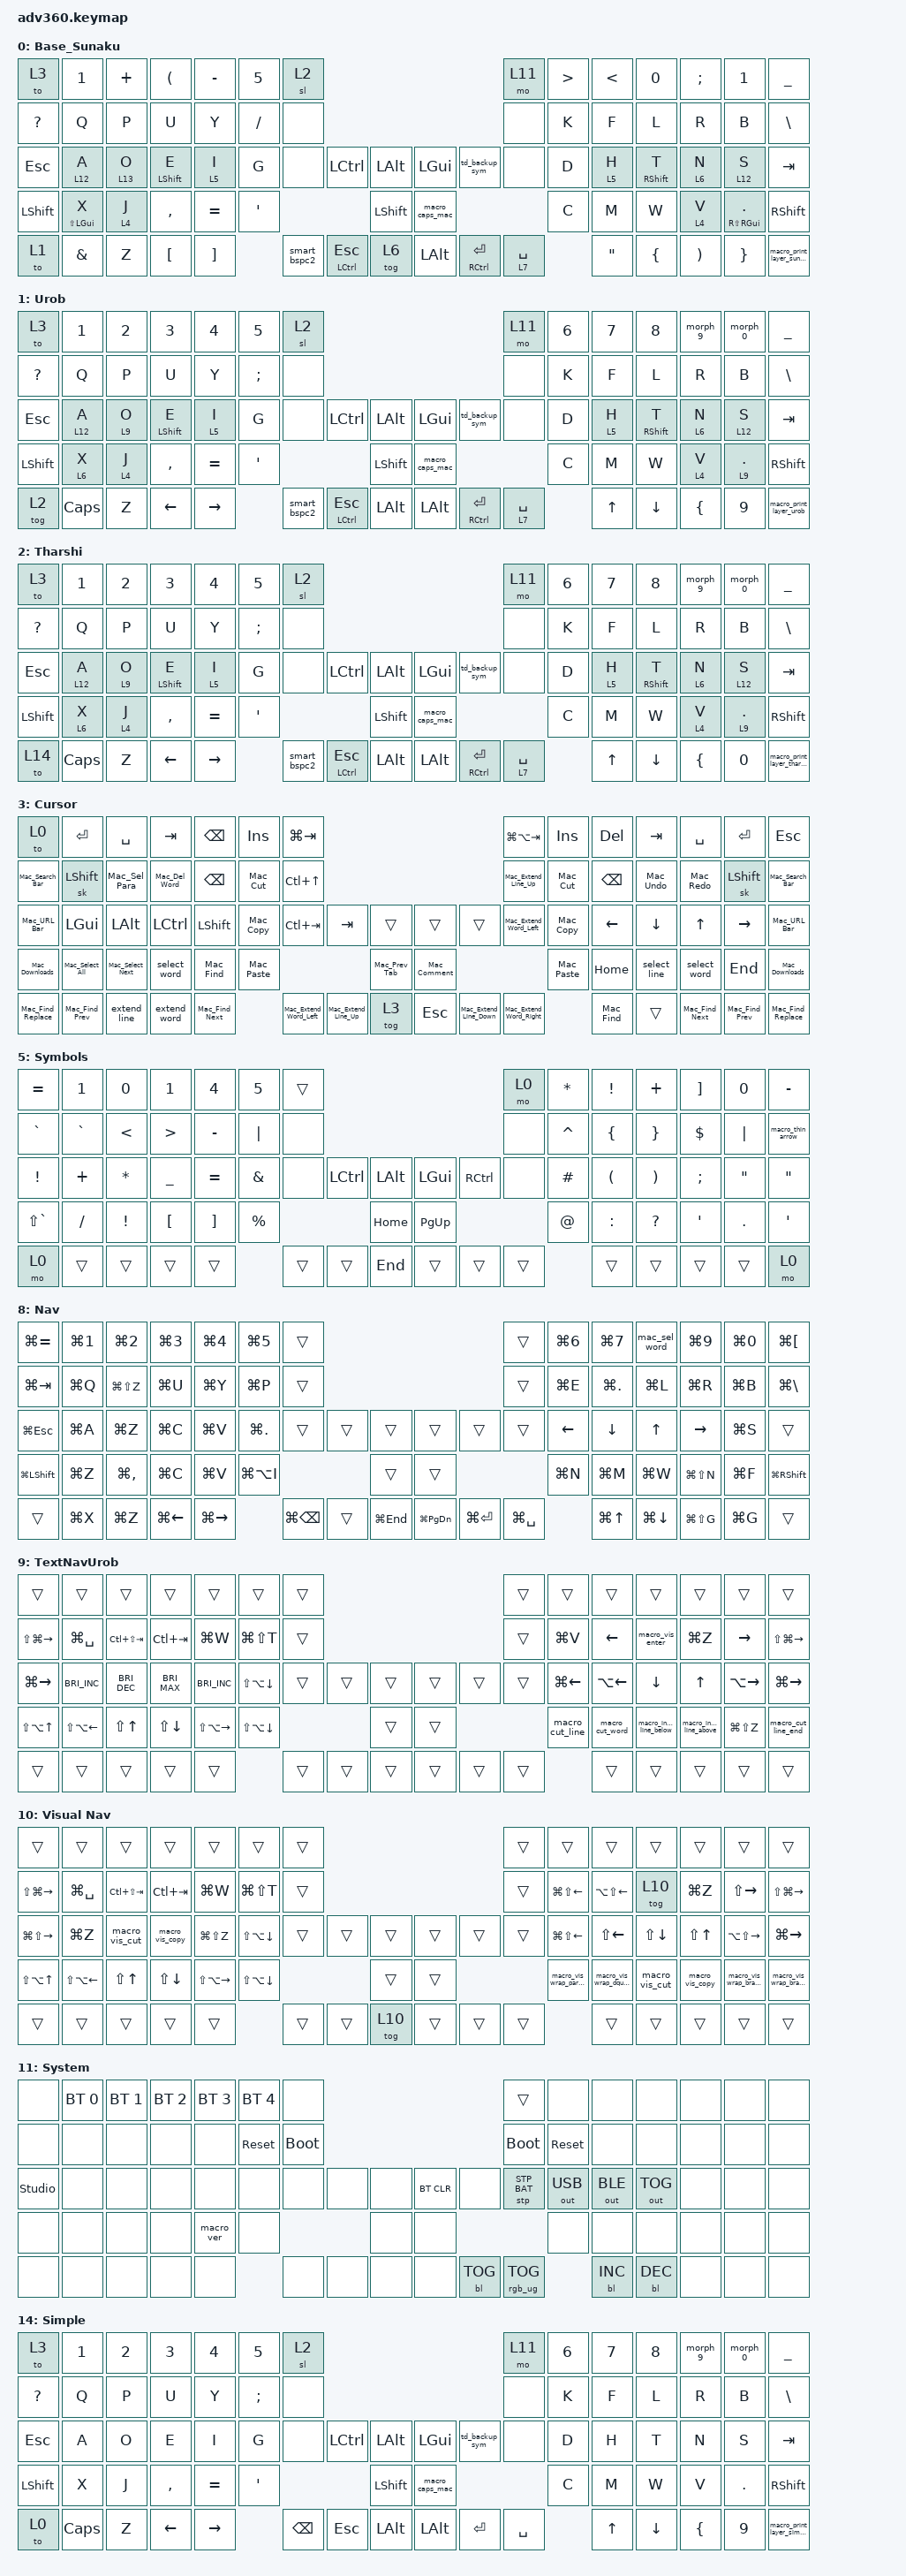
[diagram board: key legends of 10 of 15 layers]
#include <dt-bindings/zmk/stp.h>
#include <behaviors.dtsi>
#include <dt-bindings/zmk/backlight.h>
#include <dt-bindings/zmk/bt.h>
#include <dt-bindings/zmk/keys.h>
#include <dt-bindings/zmk/outputs.h>
#include <dt-bindings/zmk/rgb.h>

#define KEYS_L 0 1 2 3 4 5 6 \
               14 15 16 17 18 19 20 \
               28 29 30 31 32 33 34 \
               46 47 48 49 50 51 \
               60 61 62 63 64
#define KEYS_R 7 8 9 10 11 12 13 \
               21 22 23 24 25 26 27 \
               39 40 41 42 43 44 45 \
               54 55 56 57 58 59 \
               71 72 73 74 75
#define KEYS_THUMBS 35 36 37 38 52 53 65 66 67 68 69 70

/* Hyper layer is index 12; hyper keycodes are written out as LC(LS(LA(LG(k))))
   rather than a macro, so the Keymap Editor can still parse the bindings. */

/ {
    behaviors {
        #include "macros.dtsi"
        #include "version.dtsi"

        vis_nav_toggle: vis_nav_toggle {
            compatible = "zmk,behavior-macro";
            label = "VIS_NAV_TOGGLE";
            #binding-cells = <0>;
            wait-ms = <0>;
            tap-ms = <0>;
            bindings = <&tog 10>;
        };

        /* Enter key: Tap for Enter, Hold for Command/GUI */

        enter_cmd: enter_command {
            compatible = "zmk,behavior-hold-tap";
            label = "ENTER_COMMAND";
            #binding-cells = <2>;
            tapping-term-ms = <200>;
            quick-tap-ms = <175>;
            require-prior-idle-ms = <150>;
            flavor = "balanced";
            bindings = <&kp>, <&kp>;
        };

        /* Left thumb backspace that becomes Shift when held */

        bs_shift: backspace_shift {
            compatible = "zmk,behavior-hold-tap";
            label = "BACKSPACE_SHIFT";
            #binding-cells = <2>;
            tapping-term-ms = <220>;
            quick-tap-ms = <175>;
            require-prior-idle-ms = <160>;
            flavor = "tap-preferred";
            retro-tap;
            bindings = <&kp>, <&kp>;
        };

        /* Right thumb space that becomes Shift when held */

        sp_shift: space_shift {
            compatible = "zmk,behavior-hold-tap";
            label = "SPACE_SHIFT";
            #binding-cells = <2>;
            tapping-term-ms = <200>;
            quick-tap-ms = <175>;
            require-prior-idle-ms = <150>;
            flavor = "balanced";
            bindings = <&kp>, <&kp>;
        };

        sp_nav: space_nav {
            compatible = "zmk,behavior-hold-tap";
            label = "SPACE_NAV";
            #binding-cells = <2>;
            tapping-term-ms = <200>;
            quick-tap-ms = <175>;
            require-prior-idle-ms = <150>;
            flavor = "balanced";
            bindings = <&mo>, <&kp>;
        };

        spac_nav_sunaku: space_nav_sunaku {
            compatible = "zmk,behavior-hold-tap";
            label = "SPACE_NAV_SUNAKU";
            #binding-cells = <2>;
            tapping-term-ms = <200>;
            quick-tap-ms = <150>;
            require-prior-idle-ms = <150>;
            flavor = "tap-preferred";
            retro-tap;
            bindings = <&mo>, <&kp>;
        };

        /* Smart Toggle for Sym Layer: Tap=Sticky, DoubleTap=Toggle */
        /* Hold-Tap for Sym Layer: Hold=Momentary(1), Tap=Sticky(1) */
        /* Smart Toggle for Sym Layer: Tap=Sticky(via ht), DoubleTap=Lock(tog) */
        /* Select Word: Normal=right, Shift=left */
        /* Smart Backspace: Normal=BSPC/Shift (Hold-Tap), Shift=DelWord (Option+BSPC) */

        bs_nav: backspace_nav {
            compatible = "zmk,behavior-hold-tap";
            label = "BACKSPACE_NAV";
            #binding-cells = <2>;
            tapping-term-ms = <220>;
            quick-tap-ms = <175>;
            require-prior-idle-ms = <160>;
            flavor = "tap-preferred";
            retro-tap;
            bindings = <&mo>, <&kp>;
        };

        smart_bspc: smart_backspace {
            compatible = "zmk,behavior-mod-morph";
            label = "SMART_BACKSPACE";
            #binding-cells = <0>;
            bindings = <&bs_shift LSHFT BSPC>, <&kp LA(BSPC)>;

            mods = <(MOD_LSFT|MOD_RSFT)>;
        };

        smart_bspc2: smart_backspace_2 {
            compatible = "zmk,behavior-mod-morph";
            label = "SMART_BACKSPACE_2";
            #binding-cells = <0>;
            bindings = <&bs_nav 8 BSPC>, <&kp LA(BSPC)>;

            mods = <(MOD_LSFT|MOD_RSFT)>;
        };

        select_word: select_word {
            compatible = "zmk,behavior-mod-morph";
            label = "SELECT_WORD";
            #binding-cells = <0>;
            bindings = <&Mac_Select_Word_Right>, <&Mac_Select_Word_Left>;

            mods = <(MOD_LSFT|MOD_RSFT)>;
        };

        /* Select Line: Normal=right, Shift=left */

        select_line: select_line {
            compatible = "zmk,behavior-mod-morph";
            label = "SELECT_LINE";
            #binding-cells = <0>;
            bindings = <&Mac_Select_Line_Right>, <&Mac_Select_Line_Left>;

            mods = <(MOD_LSFT|MOD_RSFT)>;
        };

        /* Extend Word: Normal=right, Shift=left */

        extend_word: extend_word {
            compatible = "zmk,behavior-mod-morph";
            label = "EXTEND_WORD";
            #binding-cells = <0>;
            bindings = <&Mac_Extend_Word_Right>, <&Mac_Extend_Word_Left>;

            mods = <(MOD_LSFT|MOD_RSFT)>;
        };

        /* Extend Line: Normal=down, Shift=up */

        extend_line: extend_line {
            compatible = "zmk,behavior-mod-morph";
            label = "EXTEND_LINE";
            #binding-cells = <0>;
            bindings = <&Mac_Extend_Line_Down>, <&Mac_Extend_Line_Up>;

            mods = <(MOD_LSFT|MOD_RSFT)>;
        };

        /* Hold-Tap for Nav Layer: Hold=Momentary(4), Tap=Sticky(4) */
        /* Note: Double-tap to toggle is removed to fix build compatibility constraints */

        mt_ctrl_enter: mod_tap_ctrl_enter {
            compatible = "zmk,behavior-hold-tap";
            label = "MOD_TAP_CTRL_ENTER";
            #binding-cells = <2>;
            tapping-term-ms = <175>;
            quick-tap-ms = <0>;
            flavor = "tap-preferred";
            retro-tap;
            bindings = <&kp>, <&kp>;
        };

        mt_ctrl_esc: mod_tap_ctrl_esc {
            compatible = "zmk,behavior-hold-tap";
            label = "MOD_TAP_CTRL_ESC";
            #binding-cells = <2>;
            tapping-term-ms = <220>;
            quick-tap-ms = <0>;
            require-prior-idle-ms = <140>;
            flavor = "tap-preferred";
            retro-tap;
            bindings = <&kp>, <&kp>;
        };

        mt_opt_esc: mod_tap_opt_esc {
            compatible = "zmk,behavior-hold-tap";
            label = "MOD_TAP_OPT_ESC";
            #binding-cells = <2>;
            tapping-term-ms = <200>;
            quick-tap-ms = <0>;
            require-prior-idle-ms = <140>;
            flavor = "tap-preferred";
            retro-tap;
            bindings = <&kp>, <&kp>;
        };

        mt_opt_tab: mod_tap_opt_tab {
            compatible = "zmk,behavior-hold-tap";
            label = "MOD_TAP_OPT_TAB";
            #binding-cells = <2>;
            tapping-term-ms = <200>;
            quick-tap-ms = <0>;
            require-prior-idle-ms = <140>;
            flavor = "tap-preferred";
            retro-tap;
            bindings = <&kp>, <&kp>;
        };

        urob_left_index: homerow_mod_left_sym {
            compatible = "zmk,behavior-hold-tap";
            label = "HOMEROW_MOD_LEFT_SYM";
            #binding-cells = <2>;
            tapping-term-ms = <390>;
            quick-tap-ms = <150>;
            require-prior-idle-ms = <190>;
            flavor = "balanced";
            bindings = <&mo>, <&kp>;

            hold-trigger-key-positions = <KEYS_R KEYS_THUMBS>;
            hold-trigger-on-release;
        };

        sunaku_hmr_ring: homerow_mod_left_sym_sunaku_ring {
            compatible = "zmk,behavior-hold-tap";
            label = "SUNAKU_HMR_RING";
            #binding-cells = <2>;
            tapping-term-ms = <270>;
            quick-tap-ms = <300>;
            require-prior-idle-ms = <70>;
            flavor = "tap-preferred";
            retro-tap;
            bindings = <&mo>, <&kp>;

            hold-trigger-key-positions = <KEYS_R KEYS_THUMBS>;
        };

        sunaku_hmr_middle: homerow_mod_left_sym_sunaku_mid {
            compatible = "zmk,behavior-hold-tap";
            label = "SUNAKU_HMR_MIDDLE";
            #binding-cells = <2>;
            tapping-term-ms = <230>;
            quick-tap-ms = <300>;
            require-prior-idle-ms = <150>;
            flavor = "tap-preferred";
            retro-tap;
            bindings = <&kp>, <&kp>;

            hold-trigger-key-positions = <KEYS_R KEYS_THUMBS>;
        };

        sunaku_hmr_index: homerow_mod_left_sym_sunaku {
            compatible = "zmk,behavior-hold-tap";
            label = "SUNAKU_HMR_INDEX";
            #binding-cells = <2>;
            tapping-term-ms = <230>;
            quick-tap-ms = <300>;
            require-prior-idle-ms = <70>;
            flavor = "tap-preferred";
            retro-tap;
            bindings = <&mo>, <&kp>;

            hold-trigger-key-positions = <KEYS_R KEYS_THUMBS>;
        };

        sunaku_left_pinky: sunaku_left_pinky {
            compatible = "zmk,behavior-hold-tap";
            label = "SUNAKU_LEFT_PINKY";
            #binding-cells = <2>;
            tapping-term-ms = <270>;
            quick-tap-ms = <300>;
            require-prior-idle-ms = <70>;
            flavor = "tap-preferred";
            retro-tap;
            bindings = <&mo>, <&kp>;

            hold-trigger-key-positions = <KEYS_R KEYS_THUMBS>;
        };

        sunaku_left_pinky_bottom: sunaku_left_pinky_bottom {
            compatible = "zmk,behavior-hold-tap";
            label = "SUNAKU_LEFT_PINKY_BOTTOM";
            #binding-cells = <2>;
            tapping-term-ms = <270>;
            quick-tap-ms = <300>;
            require-prior-idle-ms = <70>;
            flavor = "tap-preferred";
            retro-tap;
            bindings = <&kp>, <&kp>;

            hold-trigger-key-positions = <KEYS_R KEYS_THUMBS>;
        };

        sunaku_left_ring_bottom: sunaku_left_ring_bottom {
            compatible = "zmk,behavior-hold-tap";
            label = "SUNAKU_LEFT_RING_BOTTOM";
            #binding-cells = <2>;
            tapping-term-ms = <270>;
            quick-tap-ms = <300>;
            require-prior-idle-ms = <70>;
            flavor = "tap-preferred";
            retro-tap;
            bindings = <&mo>, <&kp>;

            hold-trigger-key-positions = <KEYS_R KEYS_THUMBS>;
        };

        sunaku_right_index: sunaku_right_index {
            compatible = "zmk,behavior-hold-tap";
            label = "SUNAKU_RIGHT_INDEX";
            #binding-cells = <2>;
            tapping-term-ms = <200>;
            quick-tap-ms = <300>;
            require-prior-idle-ms = <70>;
            flavor = "tap-preferred";
            retro-tap;
            bindings = <&mo>, <&kp>;

            hold-trigger-key-positions = <KEYS_L KEYS_THUMBS>;
        };

        sunaku_right_middle: sunaku_right_middle {
            compatible = "zmk,behavior-hold-tap";
            label = "SUNAKU_RIGHT_MIDDLE";
            #binding-cells = <2>;
            tapping-term-ms = <200>;
            quick-tap-ms = <300>;
            require-prior-idle-ms = <70>;
            flavor = "tap-preferred";
            retro-tap;
            bindings = <&kp>, <&kp>;

            hold-trigger-key-positions = <KEYS_L KEYS_THUMBS>;
        };

        sunaku_right_ring: sunaku_right_ring {
            compatible = "zmk,behavior-hold-tap";
            label = "SUNAKU_RIGHT_RING";
            #binding-cells = <2>;
            tapping-term-ms = <200>;
            quick-tap-ms = <300>;
            require-prior-idle-ms = <70>;
            flavor = "tap-preferred";
            retro-tap;
            bindings = <&mo>, <&kp>;

            hold-trigger-key-positions = <KEYS_L KEYS_THUMBS>;
        };

        sunaku_right_pinky: sunaku_right_pinky {
            compatible = "zmk,behavior-hold-tap";
            label = "SUNAKU_RIGHT_PINKY";
            #binding-cells = <2>;
            tapping-term-ms = <200>;
            quick-tap-ms = <200>;
            require-prior-idle-ms = <70>;
            flavor = "tap-preferred";
            retro-tap;
            bindings = <&mo>, <&kp>;

            hold-trigger-key-positions = <KEYS_L KEYS_THUMBS>;
        };

        sunaku_right_ring_bottom: sunaku_right_ring_bottom {
            compatible = "zmk,behavior-hold-tap";
            label = "SUNAKU_RIGHT_RING_BOTTOM";
            #binding-cells = <2>;
            tapping-term-ms = <200>;
            quick-tap-ms = <300>;
            require-prior-idle-ms = <70>;
            flavor = "tap-preferred";
            retro-tap;
            bindings = <&mo>, <&kp>;

            hold-trigger-key-positions = <KEYS_L KEYS_THUMBS>;
        };

        sunaku_right_pinky_bottom: sunaku_right_pinky_bottom {
            compatible = "zmk,behavior-hold-tap";
            label = "SUNAKU_RIGHT_PINKY_BOTTOM";
            #binding-cells = <2>;
            tapping-term-ms = <200>;
            quick-tap-ms = <300>;
            require-prior-idle-ms = <70>;
            flavor = "tap-preferred";
            retro-tap;
            bindings = <&kp>, <&kp>;

            hold-trigger-key-positions = <KEYS_L KEYS_THUMBS>;
        };

        urob_left_ring: homerow_mod_left_ring_sym {
            compatible = "zmk,behavior-hold-tap";
            label = "HOMEROW_MOD_LEFT_RING_SYM";
            #binding-cells = <2>;
            tapping-term-ms = <390>;
            quick-tap-ms = <150>;
            require-prior-idle-ms = <230>;
            flavor = "balanced";
            bindings = <&mo>, <&kp>;

            hold-trigger-key-positions = <KEYS_R KEYS_THUMBS>;
            hold-trigger-on-release;
        };

        urob_right_index: homerow_mod_right_sym {
            compatible = "zmk,behavior-hold-tap";
            label = "HOMEROW_MOD_RIGHT_SYM";
            #binding-cells = <2>;
            tapping-term-ms = <280>;
            quick-tap-ms = <150>;
            require-prior-idle-ms = <150>;
            flavor = "balanced";
            bindings = <&mo>, <&kp>;

            hold-trigger-key-positions = <KEYS_L KEYS_THUMBS>;
        };

        urob_right_ring: homerow_mod_right_ring_sym {
            compatible = "zmk,behavior-hold-tap";
            label = "HOMEROW_MOD_RIGHT_RING_SYM";
            #binding-cells = <2>;
            tapping-term-ms = <280>;
            quick-tap-ms = <150>;
            require-prior-idle-ms = <150>;
            flavor = "balanced";
            bindings = <&mo>, <&kp>;

            hold-trigger-key-positions = <KEYS_L KEYS_THUMBS>;
        };

        urob_left_ring_bottom: homerow_mod_left_ring_bottom_layer {
            compatible = "zmk,behavior-hold-tap";
            label = "HOMEROW_MOD_LEFT_RING_BOTTOM_LAYER";
            #binding-cells = <2>;
            tapping-term-ms = <280>;
            quick-tap-ms = <150>;
            require-prior-idle-ms = <150>;
            flavor = "balanced";
            bindings = <&mo>, <&kp>;

            hold-trigger-key-positions = <KEYS_R KEYS_THUMBS>;
            hold-trigger-on-release;
        };

        urob_right_ring_bottom: homerow_mod_right_ring_bottom_layer {
            compatible = "zmk,behavior-hold-tap";
            label = "HOMEROW_MOD_RIGHT_RING_BOTTOM_LAYER";
            #binding-cells = <2>;
            tapping-term-ms = <280>;
            quick-tap-ms = <150>;
            require-prior-idle-ms = <70>;
            flavor = "balanced";
            bindings = <&mo>, <&kp>;

            hold-trigger-key-positions = <KEYS_L KEYS_THUMBS>;
            hold-trigger-on-release;
        };

        urob_left_middle: homerow_mod_left_shift {
            compatible = "zmk,behavior-hold-tap";
            label = "HOMEROW_MOD_LEFT_SHIFT";
            #binding-cells = <2>;
            tapping-term-ms = <370>;
            quick-tap-ms = <150>;
            require-prior-idle-ms = <230>;
            flavor = "balanced";
            bindings = <&kp>, <&kp>;

            hold-trigger-key-positions = <KEYS_R KEYS_THUMBS>;
            hold-trigger-on-release;
        };

        urob_right_middle: homerow_mod_right_shift {
            compatible = "zmk,behavior-hold-tap";
            label = "HOMEROW_MOD_RIGHT_SHIFT";
            #binding-cells = <2>;
            tapping-term-ms = <280>;
            quick-tap-ms = <150>;
            require-prior-idle-ms = <150>;
            flavor = "balanced";
            bindings = <&kp>, <&kp>;

            hold-trigger-key-positions = <KEYS_L KEYS_THUMBS>;
            hold-trigger-on-release;
        };

        urob_left_pinky: homerow_mod_left_cmd {
            compatible = "zmk,behavior-hold-tap";
            label = "HOMEROW_MOD_LEFT_CMD";
            #binding-cells = <2>;
            tapping-term-ms = <350>;
            quick-tap-ms = <150>;
            require-prior-idle-ms = <150>;
            flavor = "tap-preferred";
            bindings = <&mo>, <&kp>;

            hold-trigger-key-positions = <KEYS_R KEYS_THUMBS>;
            hold-trigger-on-release;
        };

        urob_left_pinky_bottom: homerow_mod_left_pinky_bottom_layer {
            compatible = "zmk,behavior-hold-tap";
            label = "HOMEROW_MOD_LEFT_PINKY_BOTTOM_LAYER";
            #binding-cells = <2>;
            tapping-term-ms = <280>;
            quick-tap-ms = <150>;
            require-prior-idle-ms = <150>;
            flavor = "balanced";
            bindings = <&mo>, <&kp>;

            hold-trigger-key-positions = <KEYS_R KEYS_THUMBS>;
            hold-trigger-on-release;
        };

        urob_right_pinky: homerow_mod_right_cmd {
            compatible = "zmk,behavior-hold-tap";
            label = "HOMEROW_MOD_RIGHT_CMD";
            #binding-cells = <2>;
            tapping-term-ms = <280>;
            quick-tap-ms = <150>;
            require-prior-idle-ms = <150>;
            flavor = "balanced";
            bindings = <&mo>, <&kp>;

            hold-trigger-key-positions = <KEYS_L KEYS_THUMBS>;
            hold-trigger-on-release;
        };

        urob_right_pinky_bottom: homerow_mod_right_pinky_bottom_layer {
            compatible = "zmk,behavior-hold-tap";
            label = "HOMEROW_MOD_RIGHT_PINKY_BOTTOM_LAYER";
            #binding-cells = <2>;
            tapping-term-ms = <280>;
            quick-tap-ms = <150>;
            require-prior-idle-ms = <70>;
            flavor = "balanced";
            bindings = <&mo>, <&kp>;

            hold-trigger-key-positions = <KEYS_L KEYS_THUMBS>;
            hold-trigger-on-release;
        };

        /* Smart Toggle for Nav Layer (Layer 4): Tap=Sticky, Hold=Momentary */
        /* Replaced Tap-Dance with Hold-Tap for instant speed (Option A) */
        /* Hold-Tap for Cursor Layer: Hold=Momentary(5), Tap=Sticky(5) */
        /* Smart Toggle for Sym Layer: Tap=Sticky, DoubleTap=Lock(tog) */

        td_backup_sym: tap_dance_backup_sym {
            compatible = "zmk,behavior-tap-dance";
            label = "TAP_DANCE_BACKUP_SYM";
            #binding-cells = <0>;
            tapping-term-ms = <175>;
            bindings = <&sl 10>, <&tog 10>;
        };

        /* Smart Toggle for Cursor Layer: Tap=Sticky, DoubleTap=Lock(tog) */

        td_cursor: tap_dance_cursor {
            compatible = "zmk,behavior-tap-dance";
            label = "TAP_DANCE_CURSOR";
            #binding-cells = <0>;
            tapping-term-ms = <175>;
            bindings = <&sl 3>, <&tog 3>;
        };

        fat_arrow: fat_arrow_morph {
            compatible = "zmk,behavior-mod-morph";
            label = "FAT_ARROW_MORPH";
            #binding-cells = <0>;
            bindings = <&kp MINUS>, <&macro_fat_arrow>;

            mods = <(MOD_LSFT|MOD_RSFT)>;
        };

        add_assign: add_assign_morph {
            compatible = "zmk,behavior-mod-morph";
            label = "ADD_ASSIGN_MORPH";
            #binding-cells = <0>;
            bindings = <&kp PLUS>, <&macro_add_assign>;

            mods = <(MOD_LSFT|MOD_RSFT)>;
        };

        not_equal: not_equal_morph {
            compatible = "zmk,behavior-mod-morph";
            label = "NOT_EQUAL_MORPH";
            #binding-cells = <0>;
            bindings = <&kp COLON>, <&macro_not_equal>;

            mods = <(MOD_LSFT|MOD_RSFT)>;
        };

        underscore_arrow: underscore_arrow_morph {
            compatible = "zmk,behavior-mod-morph";
            label = "UNDERSCORE_ARROW_MORPH";
            #binding-cells = <0>;
            bindings = <&kp UNDER>, <&macro_thin_arrow>;

            mods = <(MOD_LSFT|MOD_RSFT)>;
        };

        morph_9: morph_9_lbracket {
            compatible = "zmk,behavior-mod-morph";
            label = "MORPH_9_LBRACKET";
            #binding-cells = <0>;
            bindings = <&kp N9>, <&macro_lbracket>;

            mods = <(MOD_LSFT|MOD_RSFT)>;
        };

        morph_0: morph_0_rbracket {
            compatible = "zmk,behavior-mod-morph";
            label = "MORPH_0_RBRACKET";
            #binding-cells = <0>;
            bindings = <&kp N0>, <&macro_rbracket>;

            mods = <(MOD_LSFT|MOD_RSFT)>;
        };

        lcurly_sq: lcurly_square {
            compatible = "zmk,behavior-mod-morph";
            label = "LCURLY_SQUARE";
            #binding-cells = <0>;
            bindings = <&kp LBRC>, <&macro_lbracket>;

            mods = <(MOD_LSFT|MOD_RSFT)>;
        };

        rcurly_sq: rcurly_square {
            compatible = "zmk,behavior-mod-morph";
            label = "RCURLY_SQUARE";
            #binding-cells = <0>;
            bindings = <&kp RBRC>, <&macro_rbracket>;

            mods = <(MOD_LSFT|MOD_RSFT)>;
        };

        tp_sp_nav: tp_space_nav {
            compatible = "zmk,behavior-hold-tap";
            label = "TP_SPACE_NAV";
            #binding-cells = <2>;
            tapping-term-ms = <190>;
            quick-tap-ms = <0>;
            require-prior-idle-ms = <140>;
            flavor = "tap-preferred";
            retro-tap;
            bindings = <&mo>, <&kp>;
        };

        sp_nav_sunaku: sp_nav_sunaku {
            compatible = "zmk,behavior-hold-tap";
            label = "SP_NAV_SUNAKU";
            #binding-cells = <2>;
            tapping-term-ms = <130>;
            quick-tap-ms = <200>;
            require-prior-idle-ms = <60>;
            flavor = "tap-preferred";
            retro-tap;
            bindings = <&mo>, <&kp>;
        };

        hrm_left_index: tp_homerow_mod_left_sym {
            compatible = "zmk,behavior-hold-tap";
            label = "TP_HOMEROW_MOD_LEFT_SYM";
            #binding-cells = <2>;
            tapping-term-ms = <260>;
            quick-tap-ms = <200>;
            require-prior-idle-ms = <150>;
            flavor = "tap-preferred";
            retro-tap;
            bindings = <&mo>, <&kp>;

            hold-trigger-key-positions = <KEYS_R>;
            hold-trigger-on-release;
        };

        hrm_left_ring: tp_homerow_mod_left_ring_sym {
            compatible = "zmk,behavior-hold-tap";
            label = "TP_HOMEROW_MOD_LEFT_RING_SYM";
            #binding-cells = <2>;
            tapping-term-ms = <270>;
            quick-tap-ms = <200>;
            require-prior-idle-ms = <150>;
            flavor = "tap-preferred";
            retro-tap;
            bindings = <&mo>, <&kp>;

            hold-trigger-key-positions = <KEYS_R>;
            hold-trigger-on-release;
        };

        hrm_right_index: tp_homerow_mod_right_sym {
            compatible = "zmk,behavior-hold-tap";
            label = "TP_HOMEROW_MOD_RIGHT_SYM";
            #binding-cells = <2>;
            tapping-term-ms = <220>;
            quick-tap-ms = <180>;
            require-prior-idle-ms = <140>;
            flavor = "tap-preferred";
            retro-tap;
            bindings = <&mo>, <&kp>;

            hold-trigger-key-positions = <KEYS_L>;
            hold-trigger-on-release;
        };

        hrm_right_ring: tp_homerow_mod_right_ring_sym {
            compatible = "zmk,behavior-hold-tap";
            label = "TP_HOMEROW_MOD_RIGHT_RING_SYM";
            #binding-cells = <2>;
            tapping-term-ms = <230>;
            quick-tap-ms = <180>;
            require-prior-idle-ms = <140>;
            flavor = "tap-preferred";
            retro-tap;
            bindings = <&mo>, <&kp>;

            hold-trigger-key-positions = <KEYS_L>;
            hold-trigger-on-release;
        };

        hrm_left_ring_bottom: tp_homerow_mod_left_ring_bottom_layer {
            compatible = "zmk,behavior-hold-tap";
            label = "TP_HOMEROW_MOD_LEFT_RING_BOTTOM_LAYER";
            #binding-cells = <2>;
            tapping-term-ms = <250>;
            quick-tap-ms = <180>;
            require-prior-idle-ms = <150>;
            flavor = "tap-preferred";
            retro-tap;
            bindings = <&mo>, <&kp>;

            hold-trigger-key-positions = <KEYS_R>;
            hold-trigger-on-release;
        };

        hrm_right_ring_bottom: tp_homerow_mod_right_ring_bottom_layer {
            compatible = "zmk,behavior-hold-tap";
            label = "TP_HOMEROW_MOD_RIGHT_RING_BOTTOM_LAYER";
            #binding-cells = <2>;
            tapping-term-ms = <243>;
            quick-tap-ms = <180>;
            require-prior-idle-ms = <150>;
            flavor = "tap-preferred";
            retro-tap;
            bindings = <&mo>, <&kp>;

            hold-trigger-key-positions = <KEYS_L>;
            hold-trigger-on-release;
        };

        hrm_left_middle: tp_homerow_mod_left_shift {
            compatible = "zmk,behavior-hold-tap";
            label = "TP_HOMEROW_MOD_LEFT_SHIFT";
            #binding-cells = <2>;
            tapping-term-ms = <260>;
            quick-tap-ms = <180>;
            require-prior-idle-ms = <150>;
            flavor = "tap-preferred";
            retro-tap;
            bindings = <&kp>, <&kp>;

            hold-trigger-key-positions = <KEYS_R>;
            hold-trigger-on-release;
        };

        hrm_right_middle: tp_homerow_mod_right_shift {
            compatible = "zmk,behavior-hold-tap";
            label = "TP_HOMEROW_MOD_RIGHT_SHIFT";
            #binding-cells = <2>;
            tapping-term-ms = <230>;
            quick-tap-ms = <180>;
            require-prior-idle-ms = <140>;
            flavor = "tap-preferred";
            retro-tap;
            bindings = <&kp>, <&kp>;

            hold-trigger-key-positions = <KEYS_L>;
            hold-trigger-on-release;
        };

        hrm_left_pinky: tp_homerow_mod_left_cmd {
            compatible = "zmk,behavior-hold-tap";
            label = "TP_HOMEROW_MOD_LEFT_CMD";
            #binding-cells = <2>;
            tapping-term-ms = <350>;
            quick-tap-ms = <200>;
            require-prior-idle-ms = <150>;
            flavor = "tap-preferred";
            retro-tap;
            bindings = <&mo>, <&kp>;

            hold-trigger-key-positions = <KEYS_R>;
            hold-trigger-on-release;
        };

        hrm_left_pinky_bottom: tp_homerow_mod_left_pinky_bottom_layer {
            compatible = "zmk,behavior-hold-tap";
            label = "TP_HOMEROW_MOD_LEFT_PINKY_BOTTOM_LAYER";
            #binding-cells = <2>;
            tapping-term-ms = <250>;
            quick-tap-ms = <180>;
            require-prior-idle-ms = <150>;
            flavor = "tap-preferred";
            retro-tap;
            bindings = <&mo>, <&kp>;

            hold-trigger-key-positions = <KEYS_R>;
            hold-trigger-on-release;
        };

        hrm_right_pinky: tp_homerow_mod_right_cmd {
            compatible = "zmk,behavior-hold-tap";
            label = "TP_HOMEROW_MOD_RIGHT_CMD";
            #binding-cells = <2>;
            tapping-term-ms = <250>;
            quick-tap-ms = <180>;
            require-prior-idle-ms = <150>;
            flavor = "tap-preferred";
            retro-tap;
            bindings = <&mo>, <&kp>;

            hold-trigger-key-positions = <KEYS_L>;
            hold-trigger-on-release;
        };

        hrm_right_pinky_bottom: tp_homerow_mod_right_pinky_bottom_layer {
            compatible = "zmk,behavior-hold-tap";
            label = "TP_HOMEROW_MOD_RIGHT_PINKY_BOTTOM_LAYER";
            #binding-cells = <2>;
            tapping-term-ms = <243>;
            quick-tap-ms = <180>;
            require-prior-idle-ms = <150>;
            flavor = "tap-preferred";
            retro-tap;
            bindings = <&mo>, <&kp>;

            hold-trigger-key-positions = <KEYS_L>;
            hold-trigger-on-release;
        };
    };

    macros {
    };

    keymap {
        compatible = "zmk,keymap";

        sunaku_base {
            display-name = "Base_Sunaku";
            bindings = <
&to 3           &kp N1                                    &kp PLUS                      &kp LPAR                    &kp MINUS              &kp N5            &sl 2                                                                                                     &mo 11                  &kp GT  &kp LT                   &kp N0                              &kp SEMI                       &kp N1                                        &kp UNDERSCORE
&kp QUESTION    &kp Q                                     &kp P                         &kp U                       &kp Y                  &kp FSLH          &none                                                                                                     &none                   &kp K   &kp F                    &kp L                               &kp R                          &kp B                                         &kp BSLH
&kp ESCAPE      &sunaku_left_pinky 12 A                   &sunaku_hmr_ring 13 O         &sunaku_hmr_middle LSHFT E  &sunaku_hmr_index 5 I  &kp G             &none         &kp LCTRL                  &kp LEFT_ALT        &kp LEFT_GUI     &td_backup_sym              &none                   &kp D   &sunaku_right_index 5 H  &sunaku_right_middle RIGHT_SHIFT T  &sunaku_right_ring 6 N         &sunaku_right_pinky 12 S                      &kp TAB
&kp LEFT_SHIFT  &sunaku_left_pinky_bottom LS(LEFT_GUI) X  &sunaku_left_ring_bottom 4 J  &kp COMMA                   &kp EQUAL              &kp SINGLE_QUOTE                                           &kp LEFT_SHIFT      &macro_caps_mac                                                      &kp C   &kp M                    &kp W                               &sunaku_right_ring_bottom 4 V  &sunaku_right_pinky_bottom RS(RIGHT_GUI) DOT  &kp RSHFT
&to 1           &kp AMPERSAND                             &kp Z                         &kp LBKT                    &kp RBKT                                 &smart_bspc2  &mt_ctrl_esc LCTRL ESCAPE  &tog 6              &kp LALT         &mt_ctrl_enter RCTRL ENTER  &sp_nav_sunaku 7 SPACE          &kp DQT                  &kp LEFT_BRACE                      &kp RPAR                       &kp RIGHT_BRACE                               &macro_print_layer_sunaku
            >;
        };

        urob_base {
            display-name = "Urob";
            bindings = <
&to 3           &kp N1                       &kp N2                      &kp N3                     &kp N4                &kp N5            &sl 2                                                                                                     &mo 11           &kp N6  &kp N7                 &kp N8                            &morph_9                     &morph_0                        &kp UNDERSCORE
&kp QUESTION    &kp Q                        &kp P                       &kp U                      &kp Y                 &kp SEMI          &none                                                                                                     &none            &kp K   &kp F                  &kp L                             &kp R                        &kp B                           &kp BSLH
&kp ESCAPE      &urob_left_pinky 12 A        &urob_left_ring 9 O         &urob_left_middle LSHFT E  &urob_left_index 5 I  &kp G             &none         &kp LCTRL                  &kp LEFT_ALT        &kp LEFT_GUI     &td_backup_sym              &none            &kp D   &urob_right_index 5 H  &urob_right_middle RIGHT_SHIFT T  &urob_right_ring 6 N         &urob_right_pinky 12 S          &kp TAB
&kp LEFT_SHIFT  &urob_left_pinky_bottom 6 X  &urob_left_ring_bottom 4 J  &kp COMMA                  &kp EQUAL             &kp SINGLE_QUOTE                                           &kp LEFT_SHIFT      &macro_caps_mac                                               &kp C   &kp M                  &kp W                             &urob_right_ring_bottom 4 V  &urob_right_pinky_bottom 9 DOT  &kp RSHFT
&tog 2          &kp CLCK                     &kp Z                       &kp LEFT_ARROW             &kp RIGHT                               &smart_bspc2  &mt_ctrl_esc LCTRL ESCAPE  &kp LEFT_ALT        &kp LALT         &mt_ctrl_enter RCTRL ENTER  &sp_nav 7 SPACE          &kp UP_ARROW           &kp DOWN_ARROW                    &kp LEFT_BRACE               &kp N9                          &macro_print_layer_urob
            >;
        };

        tharshi_base {
            display-name = "Tharshi";
            bindings = <
&to 3           &kp N1                      &kp N2                     &kp N3                    &kp N4               &kp N5            &sl 2                                                                                                     &mo 11              &kp N6  &kp N7                &kp N8                           &morph_9                    &morph_0                       &kp UNDERSCORE
&kp QUESTION    &kp Q                       &kp P                      &kp U                     &kp Y                &kp SEMI          &none                                                                                                     &none               &kp K   &kp F                 &kp L                            &kp R                       &kp B                          &kp BSLH
&kp ESCAPE      &hrm_left_pinky 12 A        &hrm_left_ring 9 O         &hrm_left_middle LSHFT E  &hrm_left_index 5 I  &kp G             &none         &kp LCTRL                  &kp LEFT_ALT        &kp LEFT_GUI     &td_backup_sym              &none               &kp D   &hrm_right_index 5 H  &hrm_right_middle RIGHT_SHIFT T  &hrm_right_ring 6 N         &hrm_right_pinky 12 S          &kp TAB
&kp LEFT_SHIFT  &hrm_left_pinky_bottom 6 X  &hrm_left_ring_bottom 4 J  &kp COMMA                 &kp EQUAL            &kp SINGLE_QUOTE                                           &kp LEFT_SHIFT      &macro_caps_mac                                                  &kp C   &kp M                 &kp W                            &hrm_right_ring_bottom 4 V  &hrm_right_pinky_bottom 9 DOT  &kp RSHFT
&to 14          &kp CLCK                    &kp Z                      &kp LEFT_ARROW            &kp RIGHT                              &smart_bspc2  &mt_ctrl_esc LCTRL ESCAPE  &kp LEFT_ALT        &kp LALT         &mt_ctrl_enter RCTRL ENTER  &tp_sp_nav 7 SPACE          &kp UP_ARROW          &kp DOWN_ARROW                   &kp LEFT_BRACE              &kp NUMBER_0                   &macro_print_layer_tharshi
            >;
        };

        cursor {
            display-name = "Cursor";
            bindings = <
&to 0              &kp ENTER        &kp SPACE         &kp TAB        &kp BSPC        &kp INS     &kp LG(TAB)                                                                                         &kp LG(LA(TAB))         &kp INS     &kp DEL    &kp TAB         &kp SPACE       &kp ENTER       &kp ESC
&Mac_Search_Bar    &sk LSHFT        &Mac_Sel_Para     &Mac_Del_Word  &kp BSPC        &Mac_Cut    &kp LC(UP)                                                                                          &Mac_Extend_Line_Up     &Mac_Cut    &kp BSPC   &Mac_Undo       &Mac_Redo       &sk LSHFT       &Mac_Search_Bar
&Mac_URL_Bar       &kp LGUI         &kp LALT          &kp LCTRL      &kp LSHFT       &Mac_Copy   &kp LC(TAB)            &kp TAB              &trans             &trans        &trans                 &Mac_Extend_Word_Left   &Mac_Copy   &kp LEFT   &kp DOWN_ARROW  &kp UP_ARROW    &kp RIGHT       &Mac_URL_Bar
&Mac_Downloads     &Mac_Select_All  &Mac_Select_Next  &select_word   &Mac_Find       &Mac_Paste                                              &Mac_Prev_Tab      &Mac_Comment                                                 &Mac_Paste  &kp HOME   &select_line    &select_word    &kp END         &Mac_Downloads
&Mac_Find_Replace  &Mac_Find_Prev   &extend_line      &extend_word   &Mac_Find_Next              &Mac_Extend_Word_Left  &Mac_Extend_Line_Up  &tog 3             &kp ESC       &Mac_Extend_Line_Down  &Mac_Extend_Word_Right              &Mac_Find  &trans          &Mac_Find_Next  &Mac_Find_Prev  &Mac_Find_Replace
            >;
        };

        fn_media {
            display-name = "Fn/Media";
            bindings = <
&trans  &trans               &trans      &trans      &trans      &trans              &trans                                      &trans  &trans                &trans  &trans  &trans  &trans        &trans
&trans  &kp RS(RA(RC(F3)))   &kp LG(N4)  &kp LG(N5)  &kp LG(N6)  &kp C_REWIND        &trans                                      &trans  &kp LS(LG(N5))        &kp F4  &kp F5  &kp F6  &kp C_VOL_UP  &trans
&trans  &kp LG(N0)           &kp LG(N1)  &kp LG(N2)  &kp LG(N3)  &kp C_PLAY_PAUSE    &trans  &trans  &trans      &trans  &trans  &trans  &kp LS(LG(NUMBER_4))  &kp F1  &kp F2  &kp F3  &kp C_MUTE    &trans
&trans  &kp RS(RA(RC(F23)))  &kp LG(N7)  &kp LG(N8)  &kp LG(N9)  &kp C_FAST_FORWARD                  &trans      &trans                  &kp RS(LG(NUMBER_3))  &kp F7  &kp F8  &kp F9  &kp C_VOL_DN  &trans
&trans  &trans               &trans      &trans      &trans                          &trans  &trans  &trans      &trans  &trans  &trans                        &kp F7  &kp F8  &kp F9  &trans        &trans
            >;
        };

        sym {
            display-name = "Symbols";
            bindings = <
&kp EQUAL        &kp N1     &kp NUMBER_0     &kp NUMBER_1      &kp N4             &kp N5         &trans                                                 &mo 0   &kp STAR     &kp EXCLAMATION       &kp PLUS               &kp RIGHT_BRACKET  &kp N0             &kp MINUS
&kp GRAVE        &kp GRAVE  &kp LESS_THAN    &kp GREATER_THAN  &kp MINUS          &kp PIPE       &none                                                  &none   &kp CARET    &kp LEFT_BRACE        &kp RIGHT_BRACE        &kp DOLLAR         &kp PIPE           &macro_thin_arrow
&kp EXCLAMATION  &kp PLUS   &kp ASTERISK     &kp UNDERSCORE    &kp EQUAL          &kp AMPERSAND  &none   &kp LCTRL  &kp LALT      &kp LGUI   &kp RCTRL  &none   &kp HASH     &kp LEFT_PARENTHESIS  &kp RIGHT_PARENTHESIS  &kp SEMICOLON      &kp DOUBLE_QUOTES  &kp DOUBLE_QUOTES
&kp LS(GRAVE)    &kp SLASH  &kp EXCLAMATION  &kp LEFT_BRACKET  &kp RIGHT_BRACKET  &kp PERCENT                       &kp HOME      &kp PG_UP                     &kp AT_SIGN  &kp COLON             &kp QUESTION           &kp SQT            &kp DOT            &kp SINGLE_QUOTE
&mo 0            &trans     &trans           &trans            &trans                            &trans  &trans     &kp END       &trans     &trans     &trans               &trans                &trans                 &trans             &trans             &mo 0
            >;
        };

        num {
            display-name = "Numpad";
            bindings = <
&trans  &trans      &kp SLASH     &kp ASTERISK  &trans        &trans     &trans                                      &trans  &trans                 &trans                 &trans                 &trans                 &trans                 &trans
&trans  &kp COMMA   &kp NUMBER_4  &kp NUMBER_5  &kp NUMBER_6  &kp PLUS   &trans                                      &trans  &kp LS(LA(LC(LG(K))))  &kp LC(LEFT)           &kp LC(UP)             &kp LC(RIGHT)          &kp LG(LA(LC(LS(B))))  &trans
&trans  &kp N0      &kp N1        &kp N2        &kp N3        &kp EQUAL  &trans  &trans  &trans      &trans  &trans  &trans  &kp LG(LA(LC(LS(D))))  &kp LG(LA(LC(LS(H))))  &kp LG(LA(LC(LS(T))))  &kp LG(LA(LC(LS(N))))  &kp LG(LA(LC(LS(S))))  &trans
&trans  &kp PERIOD  &kp N7        &kp N8        &kp N9        &kp MINUS                  &trans      &trans                  &kp LG(NUMBER_0)       &kp LG(MINUS)          &kp LG(PLUS)           &kp D                  &kp PERIOD             &trans
&trans  &trans      &trans        &trans        &trans                   &trans  &trans  &to 0       &trans  &trans  &trans                         &kp LG(SPACE)          &trans                 &trans                 &trans                 &trans
            >;
        };

        cmd_arw_nav_right_hand {
            display-name = "Nav";
            bindings = <
&kp LG(EQUAL)     &kp LG(N1)  &kp LG(N2)  &kp LG(N3)     &kp LG(N4)     &kp LG(N5)            &trans                                                               &trans         &kp LC(LS(LA(N6)))  &kp LC(LS(LA(N7)))        &kp LC(LS(LA(N8)))          &kp LC(LS(LA(N9)))    &kp LC(LS(LA(N0)))   &kp LC(LS(LA(MINUS)))
&kp LG(QUESTION)  &kp LG(Q)   &kp LG(P)   &kp LG(U)      &kp LG(Y)      &kp LG(SEMI)          &trans                                                               &trans         &kp LC(LS(LA(K)))   &kp LC(LS(LA(F)))         &kp LC(LS(LA(L)))           &kp LC(LS(LA(R)))     &kp LC(LS(LA(B)))    &kp LC(LS(LA(BSLH)))
&kp LG(ESC)       &kp LG(A)   &kp LG(O)   &kp LG(LS(K))  &kp LG(I)      &kp LG(G)             &trans        &trans  &trans           &trans         &trans         &trans         &kp LG(D)           &kp LG(H)                 &kp LG(T)                   &kp LG(N)             &kp LG(S)            &kp LC(LS(LA(TAB)))
&kp LG(LSHFT)     &kp LG(X)   &kp LG(J)   &kp LG(COMMA)  &kp LG(EQUAL)  &kp LG(SINGLE_QUOTE)                        &trans           &trans                                       &kp LC(LS(LA(C)))   &kp LC(LS(LA(M)))         &kp LC(LS(LA(W)))           &kp LC(LS(LA(V)))     &kp LC(LS(LA(DOT)))  &trans
&trans            &kp LG(X)   &kp LG(Z)   &kp LG(LEFT)   &kp LG(RIGHT)                        &kp LG(BSPC)  &trans  &kp LG(END)      &kp LG(PG_DN)  &kp LG(ENTER)  &kp LG(SPACE)                      &kp LC(LS(LA(UP_ARROW)))  &kp LC(LS(LA(DOWN_ARROW)))  &kp LC(LS(LA(LBKT)))  &kp LC(LS(LA(N9)))   &trans
            >;
        };

        cmd_arw_nav_left_hand {
            display-name = "Nav";
            bindings = <
&kp LG(EQUAL)  &kp LG(N1)  &kp LG(N2)     &kp LG(N3)    &kp LG(N4)     &kp LG(N5)     &trans                                                               &trans         &kp LG(N6)      &kp LG(N7)      &mac_sel_word  &kp LG(N9)       &kp LG(N0)  &kp LG(LBKT)
&kp LG(TAB)    &kp LG(Q)   &kp LG(LS(Z))  &kp LG(U)     &kp LG(Y)      &kp LG(P)      &trans                                                               &trans         &kp LG(E)       &kp LG(DOT)     &kp LG(L)      &kp LG(R)        &kp LG(B)   &kp LG(BSLH)
&kp LG(ESC)    &kp LG(A)   &kp LG(Z)      &kp LG(C)     &kp LG(V)      &kp LG(DOT)    &trans        &trans  &trans           &trans         &trans         &trans         &kp LEFT_ARROW  &kp DOWN_ARROW  &kp UP_ARROW   &kp RIGHT_ARROW  &kp LG(S)   &trans
&kp LG(LSHFT)  &kp LG(Z)   &kp LG(COMMA)  &kp LG(C)     &kp LG(V)      &kp LG(LA(I))                        &trans           &trans                                       &kp LG(N)       &kp LG(M)       &kp LG(W)      &kp LG(LS(N))    &kp LG(F)   &kp LG(RSHFT)
&trans         &kp LG(X)   &kp LG(Z)      &kp LG(LEFT)  &kp LG(RIGHT)                 &kp LG(BSPC)  &trans  &kp LG(END)      &kp LG(PG_DN)  &kp LG(ENTER)  &kp LG(SPACE)                  &kp LG(UP)      &kp LG(DOWN)   &kp LG(LS(G))    &kp LG(G)   &trans
            >;
        };

        text_nav_urob {
            display-name = "TextNavUrob";
            bindings = <
&trans             &trans                &trans           &trans         &trans                &trans            &trans                                      &trans  &trans           &trans           &trans                    &trans                    &trans         &trans
&kp LS(LG(RIGHT))  &kp LG(SPACE)         &kp LC(LS(TAB))  &kp LC(TAB)    &kp LG(W)             &kp LG(LS(T))     &trans                                      &trans  &kp LG(V)        &kp LEFT         &macro_vis_enter          &kp LG(Z)                 &kp RIGHT      &kp LS(LG(RIGHT))
&kp LG(RIGHT)      &kp C_BRIGHTNESS_INC  &kp C_BRI_DEC    &kp C_BRI_MAX  &kp C_BRIGHTNESS_INC  &kp LS(LA(DOWN))  &trans  &trans  &trans      &trans  &trans  &trans  &kp LG(LEFT)     &kp LA(LEFT)     &kp DOWN                  &kp UP                    &kp LA(RIGHT)  &kp LG(RIGHT)
&kp LS(LA(UP))     &kp LS(LA(LEFT))      &kp LS(UP)       &kp LS(DOWN)   &kp LS(LA(RIGHT))     &kp LS(LA(DOWN))                  &trans      &trans                  &macro_cut_line  &macro_cut_word  &macro_insert_line_below  &macro_insert_line_above  &kp LG(LS(Z))  &macro_cut_line_end
&trans             &trans                &trans           &trans         &trans                                  &trans  &trans  &trans      &trans  &trans  &trans                   &trans           &trans                    &trans                    &trans         &trans
            >;
        };

        visual_navigation {
            display-name = "Visual Nav";
            bindings = <
&trans             &trans            &trans           &trans           &trans             &trans            &trans                                       &trans  &trans                  &trans                   &trans          &trans           &trans                    &trans
&kp LS(LG(RIGHT))  &kp LG(SPACE)     &kp LC(LS(TAB))  &kp LC(TAB)      &kp LG(W)          &kp LG(LS(T))     &trans                                       &trans  &kp LG(LS(LEFT))        &kp LA(LS(LEFT))         &tog 10         &kp LG(Z)        &kp LS(RIGHT)             &kp LS(LG(RIGHT))
&kp LG(LS(RIGHT))  &kp LG(Z)         &macro_vis_cut   &macro_vis_copy  &kp LG(LS(Z))      &kp LS(LA(DOWN))  &trans  &trans  &trans       &trans  &trans  &trans  &kp LG(LS(LEFT))        &kp LS(LEFT)             &kp LS(DOWN)    &kp LS(UP)       &kp LA(LS(RIGHT))         &kp LG(RIGHT)
&kp LS(LA(UP))     &kp LS(LA(LEFT))  &kp LS(UP)       &kp LS(DOWN)     &kp LS(LA(RIGHT))  &kp LS(LA(DOWN))                  &trans       &trans                  &macro_vis_wrap_parens  &macro_vis_wrap_dquotes  &macro_vis_cut  &macro_vis_copy  &macro_vis_wrap_brackets  &macro_vis_wrap_braces
&trans             &trans            &trans           &trans           &trans                               &trans  &trans  &tog 10      &trans  &trans  &trans                          &trans                   &trans          &trans           &trans                    &trans
            >;
        };

        system {
            display-name = "System";
            bindings = <
&none           &bt BT_SEL 0  &bt BT_SEL 1  &bt BT_SEL 2  &bt BT_SEL 3  &bt BT_SEL 4  &none                                                  &trans           &none         &none         &none         &none  &none  &none
&none           &none         &none         &none         &none         &sys_reset    &bootloader                                            &bootloader      &sys_reset    &none         &none         &none  &none  &none
&studio_unlock  &none         &none         &none         &none         &none         &none        &none  &none      &bt BT_CLR  &none       &stp STP_BAT     &out OUT_USB  &out OUT_BLE  &out OUT_TOG  &none  &none  &none
&none           &none         &none         &none         &macro_ver    &none                             &none      &none                                    &none         &none         &none         &none  &none  &none
&none           &none         &none         &none         &none                       &none        &none  &none      &none       &bl BL_TOG  &rgb_ug RGB_TOG                &bl BL_INC    &bl BL_DEC    &none  &none  &none
            >;
        };

        hyper {
            display-name = "Hyper";
            bindings = <
&trans                     &kp LC(LS(LA(LG(N1))))  &kp LC(LS(LA(LG(N2))))  &kp LC(LS(LA(LG(N3))))          &kp LC(LS(LA(LG(N4))))     &kp LC(LS(LA(LG(N5))))            &trans                                                         &trans  &kp LC(LS(LA(LG(N6))))  &kp LC(LS(LA(LG(N7))))        &kp LC(LS(LA(LG(N8))))          &kp LC(LS(LA(LG(N9))))    &kp LC(LS(LA(LG(N0))))   &kp LC(LS(LA(LG(MINUS))))
&kp LC(LS(LA(LG(SLASH))))  &kp LC(LS(LA(LG(Q))))   &kp LC(LS(LA(LG(P))))   &kp LC(LS(LA(LG(U))))           &kp LC(LS(LA(LG(Y))))      &kp LC(LS(LA(LG(SEMI))))          &trans                                                         &trans  &kp LC(LS(LA(LG(K))))   &kp LC(LS(LA(LG(F))))         &kp LC(LS(LA(LG(L))))           &kp LC(LS(LA(LG(R))))     &kp LC(LS(LA(LG(B))))    &kp LC(LS(LA(LG(BSLH))))
&trans                     &kp LC(LS(LA(LG(A))))   &kp LC(LS(LA(LG(O))))   &kp LC(LS(LA(LG(E))))           &kp LC(LS(LA(LG(I))))      &kp LC(LS(LA(LG(G))))             &trans  &trans  &trans      &trans  &trans                     &trans  &kp LC(LS(LA(LG(D))))   &kp LC(LS(LA(LG(H))))         &kp LC(LS(LA(LG(T))))           &kp LC(LS(LA(LG(N))))     &kp LC(LS(LA(LG(S))))    &trans
&trans                     &kp LC(LS(LA(LG(X))))   &kp LC(LS(LA(LG(J))))   &kp LC(LS(LA(LG(COMMA))))       &kp LC(LS(LA(LG(EQUAL))))  &kp LC(LS(LA(LG(SINGLE_QUOTE))))                  &trans      &trans                                     &kp LC(LS(LA(LG(C))))   &kp LC(LS(LA(LG(M))))         &kp LC(LS(LA(LG(W))))           &kp LC(LS(LA(LG(V))))     &kp LC(LS(LA(LG(DOT))))  &trans
&trans                     &trans                  &kp LC(LS(LA(LG(Z))))   &kp LC(LS(LA(LG(LEFT_ARROW))))  &kp LC(LS(LA(LG(RIGHT))))                                    &trans  &trans  &trans      &trans  &kp LC(LS(LA(LG(ENTER))))  &trans                          &kp LC(LS(LA(LG(UP_ARROW))))  &kp LC(LS(LA(LG(DOWN_ARROW))))  &kp LC(LS(LA(LG(LBKT))))  &kp LC(LS(LA(LG(N9))))   &trans
            >;
        };

        text_nav {
            display-name = "TextNav";
            bindings = <
&trans  &trans             &trans             &trans     &trans         &trans             &trans                                                                &trans  &trans           &trans             &trans                &trans           &trans             &trans
&trans  &kp LC(LS(TAB))    &kp LC(TAB)        &kp LG(W)  &kp LG(LS(T))  &kp LC(LA(LS(K)))  &trans                                                                &trans  &kp LG(LEFT)     &kp LC(LA(LS(O)))  &kp LC(LA(LS(I)))     &kp LG(RIGHT)    &kp LC(LA(LS(S)))  &trans
&trans  &trans             &trans             &trans     &trans         &kp LC(LA(LS(J)))  &trans    &kp LG(Z)  &kp LG(LS(Z))      &kp LSHFT  &kp ESCAPE         &trans  &kp LA(LEFT)     &kp LG(DOWN)       &kp LG(UP)            &kp LA(RIGHT)    &kp LC(LA(LS(E)))  &trans
&trans  &kp LC(LA(LS(U)))  &kp LC(LA(LS(X)))  &kp PG_DN  &kp PG_UP      &kp LC(LA(LS(P)))                       &trans             &trans                                &macro_cut_line  &macro_cut_word    &macro_cut_paragraph  &vis_nav_toggle  &mac_dup_line      &trans
&trans  &trans             &trans             &trans     &trans                            &kp BSPC  &kp DEL    &trans             &trans     &kp LC(LA(LS(V)))  &trans                   &trans             &trans                &trans           &trans             &trans
            >;
        };

        simple {
            display-name = "Simple";
            bindings = <
&to 3           &kp N1    &kp N2  &kp N3          &kp N4     &kp N5            &sl 2                                                                      &mo 11     &kp N6  &kp N7        &kp N8          &morph_9        &morph_0  &kp UNDERSCORE
&kp QUESTION    &kp Q     &kp P   &kp U           &kp Y      &kp SEMI          &none                                                                      &none      &kp K   &kp F         &kp L           &kp R           &kp B     &kp BSLH
&kp ESCAPE      &kp A     &kp O   &kp E           &kp I      &kp G             &none     &kp LCTRL   &kp LEFT_ALT        &kp LEFT_GUI     &td_backup_sym  &none      &kp D   &kp H         &kp T           &kp N           &kp S     &kp TAB
&kp LEFT_SHIFT  &kp X     &kp J   &kp COMMA       &kp EQUAL  &kp SINGLE_QUOTE                        &kp LEFT_SHIFT      &macro_caps_mac                             &kp C   &kp M         &kp W           &kp V           &kp DOT   &kp RSHFT
&to 0           &kp CLCK  &kp Z   &kp LEFT_ARROW  &kp RIGHT                    &kp BSPC  &kp ESCAPE  &kp LEFT_ALT        &kp LALT         &kp ENTER       &kp SPACE          &kp UP_ARROW  &kp DOWN_ARROW  &kp LEFT_BRACE  &kp N9    &macro_print_layer_simple
            >;
        };
    };
};
